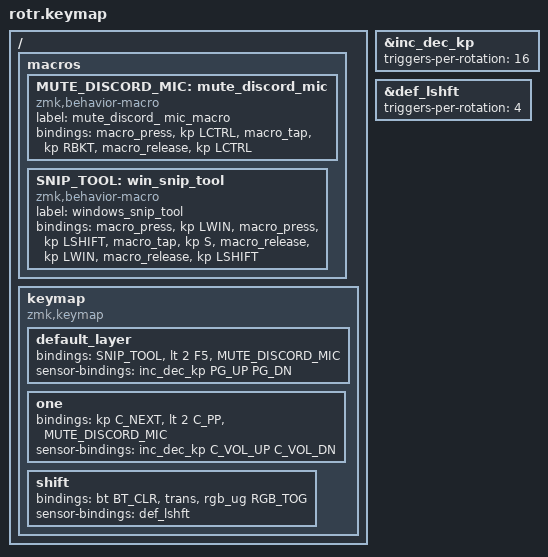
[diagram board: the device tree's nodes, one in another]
#include <behaviors.dtsi>
#include <dt-bindings/zmk/keys.h>
#include <dt-bindings/zmk/rgb.h>
#include <dt-bindings/zmk/bt.h>

&inc_dec_kp {
	triggers-per-rotation = <16>;
};
&def_lshft {
	triggers-per-rotation = <4>;
};

/ {
	macros {
		MUTE_DISCORD_MIC: mute_discord_mic {
		label = "mute_discord_ mic_macro";
		compatible = "zmk,behavior-macro";
		#binding-cells = <0>;
		bindings
			= <&macro_press &kp LCTRL>
			, <&macro_tap &kp RBKT>
			, <&macro_release &kp LCTRL>
			;
		};
		
		SNIP_TOOL: win_snip_tool {
		label = "windows_snip_tool";
		compatible = "zmk,behavior-macro";
		#binding-cells = <0>;
		bindings
			= <&macro_press &kp LWIN>
			, <&macro_press &kp LSHIFT>
			, <&macro_tap &kp S>
			, <&macro_release &kp LWIN>
			, <&macro_release &kp LSHIFT>
			;
		};
	};
};

/ {
	keymap {
		compatible = "zmk,keymap";

		default_layer {
			// RED: SNIP | F5 | MUTE MIC (SCROLL PAGE)
			bindings = <&SNIP_TOOL &lt 2 F5 &MUTE_DISCORD_MIC>;
			sensor-bindings = <&inc_dec_kp PG_UP PG_DN>;
		};
		one {
			// YELLOW: NEXT | PLAY/PAUSE | MUTE MIC (VOLUME)
			bindings = <&kp C_NEXT &lt 2 C_PP &MUTE_DISCORD_MIC>;
			sensor-bindings = <&inc_dec_kp C_VOL_UP C_VOL_DN>;
		};
		shift {
			// LAYERS: Hold MIDDLE & SPIN to cycle layers
			bindings = <&bt BT_CLR &trans &rgb_ug RGB_TOG>;
			sensor-bindings = <&def_lshft>;
		};
	};
};
